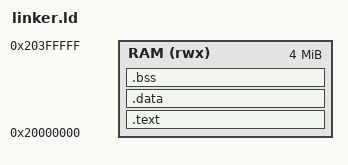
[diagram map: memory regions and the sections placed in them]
ENTRY(_start)

MEMORY
{
  RAM (rwx) : ORIGIN = 0x20000000, LENGTH = 4M
}

_estack = ORIGIN(RAM) + LENGTH(RAM);

SECTIONS
{
  .text :
  {
    . = ALIGN(4);
    KEEP(*(.text.startup))
    *(.text)
    *(.text.*)
    *(.rodata)
    *(.rodata.*)
    . = ALIGN(4);
    _etext = .;
  } > RAM

  _sidata = LOADADDR(.data);
  .data :
  {
    . = ALIGN(4);
    _sdata = .;
    *(.data)
    *(.data.*)
    . = ALIGN(4);
    _edata = .;
  } > RAM AT> RAM

  .bss :
  {
    . = ALIGN(4);
    _sbss = .;
    *(.bss)
    *(.bss.*)
    *(COMMON)
    . = ALIGN(4);
    _ebss = .;
  } > RAM

  /DISCARD/ :
  {
    *(.ARM.exidx*)
    *(.ARM.extab*)
    *(.comment)
    *(.note.*)
  }
}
